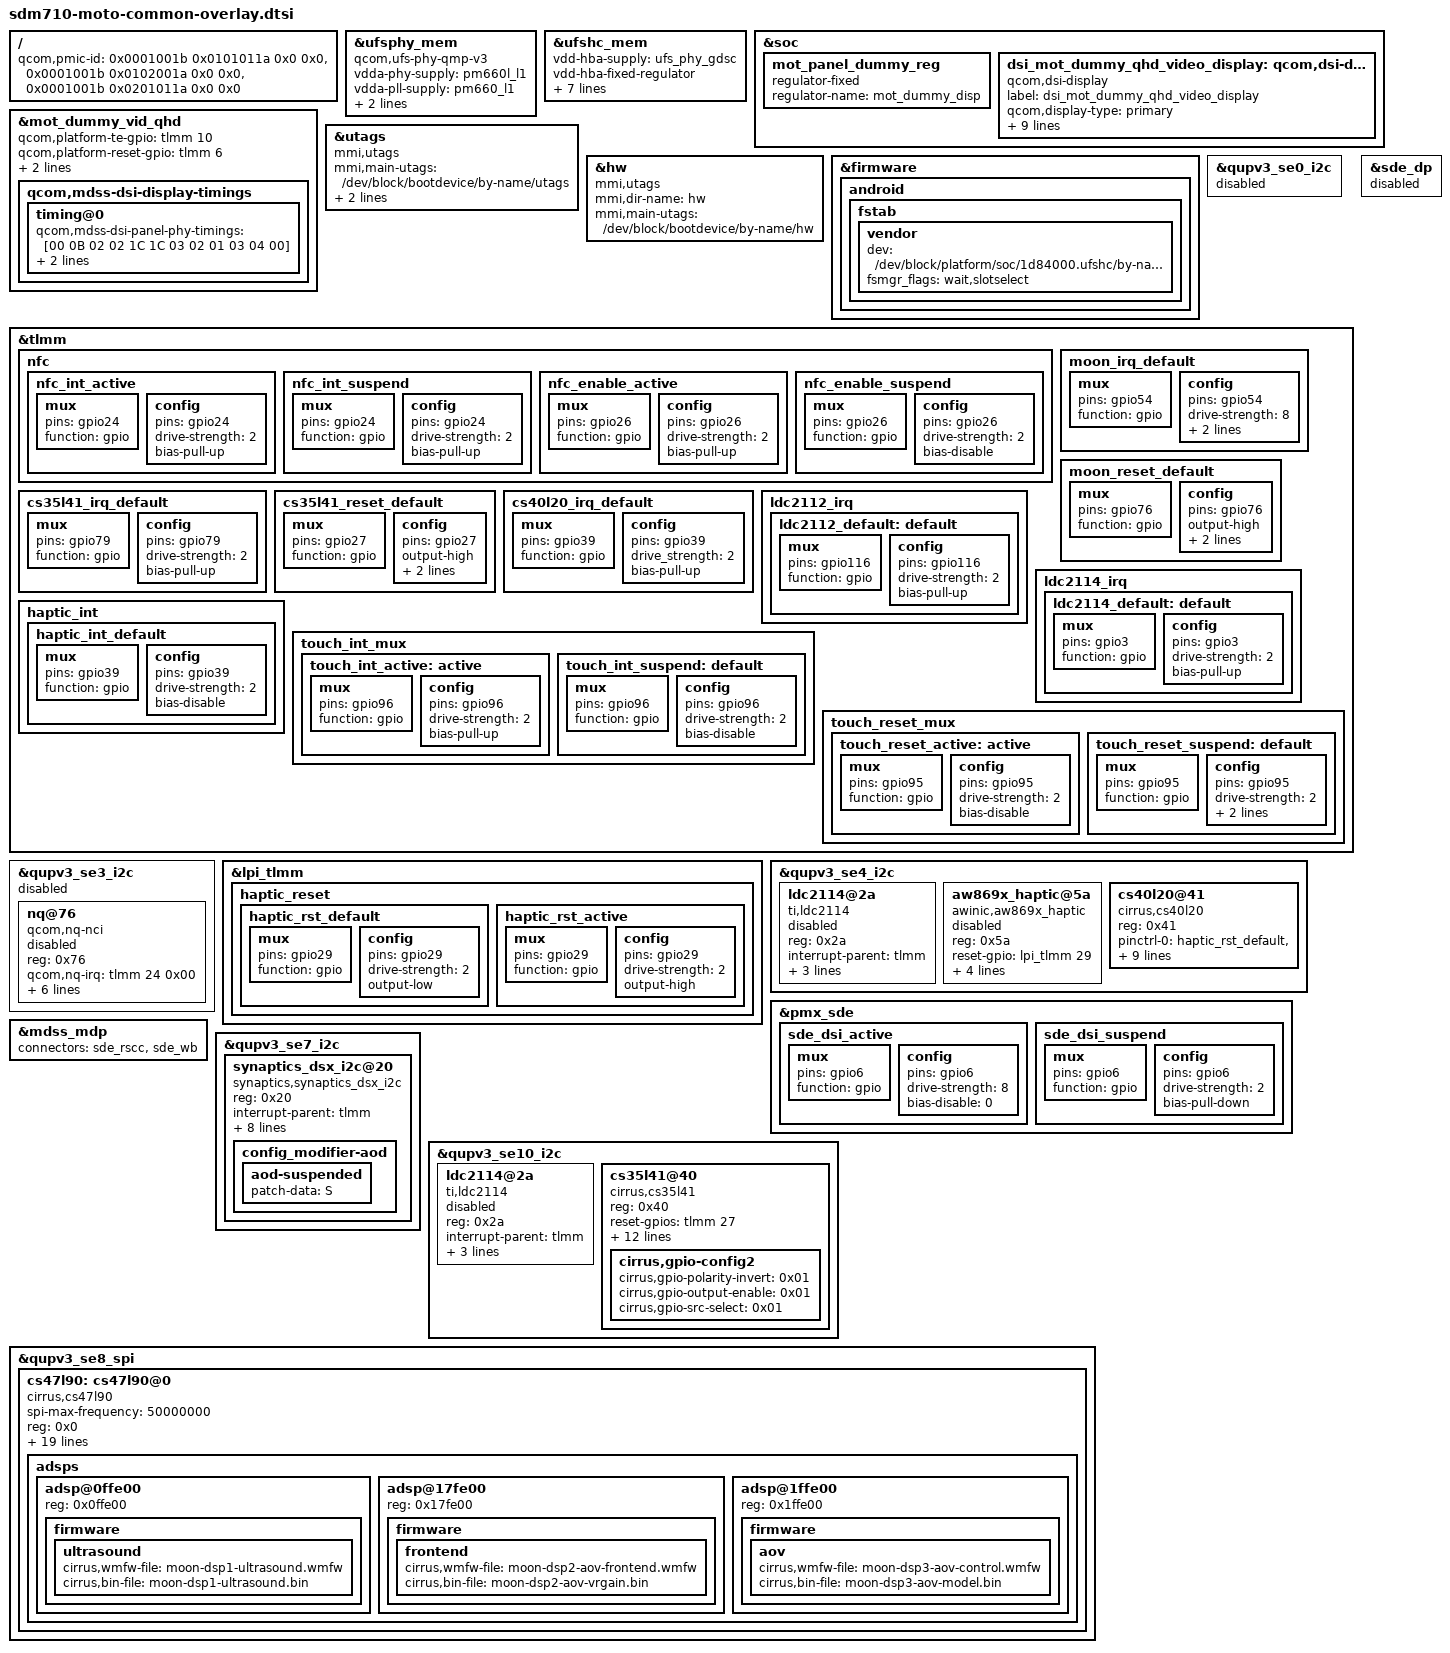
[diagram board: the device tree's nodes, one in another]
/* Copyright (c) 2018, The Linux Foundation. All rights reserved.
 *
 * This program is free software; you can redistribute it and/or modify
 * it under the terms of the GNU General Public License version 2 and
 * only version 2 as published by the Free Software Foundation.
 *
 * This program is distributed in the hope that it will be useful,
 * but WITHOUT ANY WARRANTY; without even the implied warranty of
 * MERCHANTABILITY or FITNESS FOR A PARTICULAR PURPOSE.  See the
 * GNU General Public License for more details.
 */

#include <dt-bindings/gpio/gpio.h>
#include <dt-bindings/input/input.h>
#include <dt-bindings/thermal/thermal.h>
#include <dt-bindings/clock/qcom,gcc-sdm845.h>
#include <dt-bindings/clock/qcom,camcc-sdm845.h>
#include <dt-bindings/clock/qcom,dispcc-sdm845.h>
#include <dt-bindings/clock/qcom,rpmh.h>
#include <dt-bindings/interrupt-controller/arm-gic.h>
#include "sdm670-pmic-overlay.dtsi"
#include "dsi-panel-mot-dummy-qhd-video.dtsi"
#include "sdm710-moto-audio-overlay.dtsi"

/*
 * Including features only applicable to Olson here
 */
/ {
	qcom,pmic-id = <0x0001001b 0x0101011a 0x0 0x0>,
		       <0x0001001b 0x0102001a 0x0 0x0>,
		       <0x0001001b 0x0201011a 0x0 0x0>;
};

&ufsphy_mem {
	compatible = "qcom,ufs-phy-qmp-v3";

	vdda-phy-supply = <&pm660l_l1>; /* 0.88v */
	vdda-pll-supply = <&pm660_l1>; /* 1.2v */
	vdda-phy-max-microamp = <62900>;
	vdda-pll-max-microamp = <18300>;

	status = "ok";
};

&ufshc_mem {
	vdd-hba-supply = <&ufs_phy_gdsc>;
	vdd-hba-fixed-regulator;
	vcc-supply = <&pm660l_l4>;
	vcc-voltage-level = <2960000 2960000>;
	vccq2-supply = <&pm660_l8>;
	vcc-max-microamp = <600000>;
	vccq2-max-microamp = <600000>;

	qcom,vddp-ref-clk-supply = <&pm660_l1>;
	qcom,vddp-ref-clk-max-microamp = <100>;

	status = "ok";
};

&soc {
	mot_panel_dummy_reg: mot_panel_dummy_reg {
		compatible = "regulator-fixed";
		regulator-name = "mot_dummy_disp";
	};


	dsi_mot_dummy_qhd_video_display: qcom,dsi-display@19 {
		compatible = "qcom,dsi-display";
		label = "dsi_mot_dummy_qhd_video_display";
		qcom,display-type = "primary";
		qcom,dsi-display-active;

		qcom,dsi-ctrl = <&mdss_dsi0>;
		qcom,dsi-phy = <&mdss_dsi_phy0>;
		clocks = <&mdss_dsi0_pll BYTECLK_MUX_0_CLK>,
			<&mdss_dsi0_pll PCLK_MUX_0_CLK>;
		clock-names = "src_byte_clk", "src_pixel_clk";

		pinctrl-names = "panel_active", "panel_suspend";
		pinctrl-0 = <&sde_dsi_active>;
		pinctrl-1 = <&sde_dsi_suspend>;

		qcom,dsi-panel = <&mot_dummy_vid_qhd>;
		vci_disp-supply = <&mot_panel_dummy_reg>;
	};
};

&mot_dummy_vid_qhd {
	qcom,platform-te-gpio = <&tlmm 10 0>;
	qcom,platform-reset-gpio = <&tlmm 6 0>;
	qcom,mdss-dsi-t-clk-post = <0x09>;
	qcom,mdss-dsi-t-clk-pre = <0x15>;
	qcom,mdss-dsi-display-timings {
		timing@0{
			qcom,mdss-dsi-panel-phy-timings = [00 0B 02 02 1C 1C 03
							02 01 03 04 00];
			qcom,display-topology = <1 0 1>;
			qcom,default-topology-index = <0>;
		};
	};
};

&utags {
	compatible = "mmi,utags";
	mmi,main-utags = "/dev/block/bootdevice/by-name/utags";
	mmi,backup-utags = "/dev/block/bootdevice/by-name/utagsBackup";
};

&hw {
	compatible = "mmi,utags";
	mmi,dir-name = "hw";
	mmi,main-utags = "/dev/block/bootdevice/by-name/hw";
};

&firmware {
	android {
		fstab {
			vendor {
				dev = "/dev/block/platform/soc/1d84000.ufshc/by-name/vendor";
				fsmgr_flags = "wait,slotselect";
			};
		};
	};
};

&qupv3_se0_i2c { /* FIXME: Main Proximity, Magnetometer, Barometer, Cirrus Codec */
	status = "disabled";
};

&tlmm {
	nfc {
		nfc_int_active: nfc_int_active {
			mux {
				pins = "gpio24";
				function = "gpio";
			};

			config {
				pins = "gpio24";
				drive-strength = <2>; /* 2 MA */
				bias-pull-up;
			};
		};

		nfc_int_suspend: nfc_int_suspend {
			mux {
				pins = "gpio24";
				function = "gpio";
			};

			config {
				pins = "gpio24";
				drive-strength = <2>; /* 2 MA */
				bias-pull-up;
			};
		};

		nfc_enable_active: nfc_enable_active {
			mux {
				pins = "gpio26";
				function = "gpio";
			};

			config {
				pins = "gpio26";
				drive-strength = <2>; /* 2 MA */
				bias-pull-up;
			};
		};

		nfc_enable_suspend: nfc_enable_suspend {
			mux {
				pins = "gpio26";
				function = "gpio";
			};

			config {
				pins = "gpio26";
				drive-strength = <2>; /* 2 MA */
				bias-disable;
			};
		};
	};

	moon_irq_default: moon_irq_default {
		mux {
			pins = "gpio54";
			function = "gpio";
		};

		config {
			pins = "gpio54";
			drive-strength = <8>;
			bias-pull-up;
			/* FIXME - to avoid interrupt storm */
			output-high;
		};
	};

	moon_reset_default: moon_reset_default {
		mux {
			pins = "gpio76";
			function = "gpio";
		};
		config {
			pins = "gpio76";
			output-high;
			bias-pull-up;
			drive-strength = <2>;
		};
	};

	cs35l41_irq_default: cs35l41_irq_default {
		mux {
			pins = "gpio79";
			function = "gpio";
		};
		config {
			pins = "gpio79";
			drive-strength = <2>;
			bias-pull-up;
		};
	};

	cs35l41_reset_default: cs35l41_reset_default {
		mux {
			pins = "gpio27";
			function = "gpio";
		};
		config {
			pins = "gpio27";
			output-high;
			bias-pull-up;
			drive-strength = <2>;
		};
	};

	cs40l20_irq_default: cs40l20_irq_default {
		mux {
			pins = "gpio39";
			function = "gpio";
		};
		config {
			pins = "gpio39";
			drive_strength = <2>;
			bias-pull-up;
		};
	};
};

&qupv3_se3_i2c {
	status = "disabled";
	nq@76 { /* FIXME: enable bus as well when ready */
		status = "disabled";
		compatible = "qcom,nq-nci";
		reg = <0x76>;
		qcom,nq-irq = <&tlmm 24 0x00>;
		qcom,nq-ven = <&tlmm 26 0x00>;
		qcom,nq-firm = <&tlmm 43 0x00>;
		interrupt-parent = <&tlmm>;
		interrupts = <24 0>;
		interrupt-names = "nfc_irq";
		pinctrl-names = "nfc_active", "nfc_suspend";
		pinctrl-0 = <&nfc_int_active &nfc_enable_active>;
		pinctrl-1 = <&nfc_int_suspend &nfc_enable_suspend>;
	};
};

&tlmm {
	ldc2112_irq { /* TI,LDC2112 */
		ldc2112_default: default {
			mux {
				pins = "gpio116";
				function = "gpio";
			};
			config {
				pins = "gpio116";
				drive-strength = <2>;
				bias-pull-up;
			};
		};
	};

	ldc2114_irq { /* TI,LDC2114 */
		ldc2114_default: default {
			mux {
				pins = "gpio3";
				function = "gpio";
			};
			config {
				pins = "gpio3";
				drive-strength = <2>;
				bias-pull-up;
			};
		};
	};

	haptic_int {
		haptic_int_default: haptic_int_default {
			mux {
				pins = "gpio39";
				function = "gpio";
			};

			config {
				pins = "gpio39";
				drive-strength = <2>; /* 2 mA */
				bias-disable;
			};
		};
	};
};


&lpi_tlmm {
	haptic_reset {
		haptic_rst_default: haptic_rst_default {
			mux {
				pins = "gpio29";
				function = "gpio";
			};

			config {
				pins = "gpio29";
				drive-strength = <2>; /* 2 mA */
				output-low;
			};
		};

		haptic_rst_active: haptic_rst_active {
			mux {
				pins = "gpio29";
				function = "gpio";
			};

			config {
				pins = "gpio29";
				drive-strength = <2>; /* 2 mA */
				output-high;
			};
		};
	};
};

&qupv3_se4_i2c { /* FIXME: LP4 Fan, Main Board FuelGauge, Base InductiveKeys, HapticDriver */
	status = "okay";
	ldc2114@2a {
		status = "disabled";
		compatible = "ti,ldc2114";
		reg = <0x2a>;
		interrupt-parent = <&tlmm>;
		interrupts = <116 0>;
		gpios = <&tlmm 13 0>;
		pinctrl-names = "default";
		pinctrl-0 = <&ldc2112_default>;
	};

	aw869x_haptic@5a {
		status = "disabled";
		compatible = "awinic,aw869x_haptic";
		reg = <0x5a>;
		reset-gpio = <&lpi_tlmm 29 0>;
		irq-gpio = <&tlmm 39 0>;
		pinctrl-names = "aw869x_rst0", "aw869x_rst1", "aw869x_eint";
		pinctrl-0 = <&haptic_rst_default>;
		pinctrl-1 = <&haptic_rst_active>;
		pinctrl-2 = <&haptic_int_default>;
	};

	cs40l20@41 {
		status = "ok";
		compatible = "cirrus,cs40l20";
		reg = <0x41>;
		pinctrl-names = "default";
		pinctrl-0 = <&haptic_rst_default &cs40l20_irq_default>;
		reset-gpios = <&lpi_tlmm 29 0>;
		irq-gpios = <&tlmm 39 0>;
		interrupt-parent = <&tlmm>;
		VA-supply = <&pm660_l13>;
		clock-names = "hap_ref_clk";
		clocks = <&clock_audio_lnbb AUDIO_PMIC_LNBB_CLK>;
		cirrus,boost-ind-nanohenry = <1000>;
		cirrus,boost-cap-microfarad = <4>;
		cirrus,boost-ipk-milliamp = <4500>;
	};

};

&tlmm {
	touch_int_mux {
		touch_int_active: active {
			mux {
				pins = "gpio96";
				function = "gpio";
			};
			config {
				pins = "gpio96";
				drive-strength = <2>;
				bias-pull-up;
			};
		};

		touch_int_suspend: default {
			mux {
				pins = "gpio96";
				function = "gpio";
			};
			config {
				pins = "gpio96";
				drive-strength = <2>;
				bias-disable;
			};
		};
	};

	touch_reset_mux {
		touch_reset_active: active {
			mux {
				pins = "gpio95";
				function = "gpio";
			};
			config {
				pins = "gpio95";
				drive-strength = <2>;
				bias-disable;
			};
		};

		touch_reset_suspend: default {
			mux {
				pins = "gpio95";
				function = "gpio";
			};
			config {
				pins = "gpio95";
				drive-strength = <2>;
				bias-pull-down;
				output-low;
			};
		};
	};
};

&pmx_sde {
	sde_dsi_active: sde_dsi_active {
		mux {
			pins = "gpio6";
			function = "gpio";
		};

		config {
			pins = "gpio6";
			drive-strength = <8>;    /* 8 mA */
			bias-disable = <0>;   /* no pull */
		};
	};

	sde_dsi_suspend: sde_dsi_suspend {
		mux {
			pins = "gpio6";
			function = "gpio";
		};

		config {
			pins = "gpio6";
			drive-strength = <2>;    /* 2 mA */
			bias-pull-down;          /* PULL DOWN */
		};
	};
};

&sde_dp {
	status = "disabled";
};

&mdss_mdp {
	connectors = <&sde_rscc &sde_wb>;
};

&qupv3_se7_i2c {
	status = "ok";
	synaptics_dsx_i2c@20 {
		status = "ok";
		compatible = "synaptics,synaptics_dsx_i2c";
		reg = <0x20>;
		interrupt-parent = <&tlmm>;
		interrupts = <96 0>;
		gpios = <&tlmm 96 0>, /* IRQ */
			<&tlmm 95 0>; /* RESET */
		synaptics,gpio-config;
		pinctrl-names = "default", "active";
		pinctrl-0 = <&touch_reset_suspend &touch_int_suspend>;
		pinctrl-1 = <&touch_reset_active &touch_int_active>;
		config_modifier-names = "aod";
		config_modifier-aod {
			aod-suspended {
				/* Power->sleep; */
				patch-data = "S";
			};
		};
	};
};

&qupv3_se10_i2c { /* FIXME: CapSence, Womack, FLIP FuelGauge, InductiveKeys, Laser, LS Fan */
	status = "ok";

	ldc2114@2a {
		status = "disabled";
		compatible = "ti,ldc2114";
		reg = <0x2a>;
		interrupt-parent = <&tlmm>;
		interrupts = <3 0>;
		gpios = <&tlmm 16 0>;
		pinctrl-names = "default";
		pinctrl-0 = <&ldc2114_default>;
	};

	cs35l41@40 {
		status = "ok";
		compatible = "cirrus,cs35l41";
		reg = <0x40>;
		reset-gpios = <&tlmm 27 0>;
		interrupts = <79 0>;
		interrupt-parent = <&tlmm>;
		interrupt-names = "prince_irq";

		VA-supply = <&pm660_l13>;
		VP-supply = <&pm660_l13>;

		pinctrl-names = "default";
		pinctrl-0 = <&cs35l41_irq_default &cs35l41_reset_default>;

		cirrus,left-channel-amp;
		cirrus,boost-ind-nanohenry = <1000>; /* 1uH */
		cirrus,boost-ctl-millivolt = <11000>;
		cirrus,boost-peak-milliamp = <4500>;
		cirrus,boost-cap-microfarad = <21>;
		cirrus,amp-gain-zc;

		cirrus,gpio-config2 {
			cirrus,gpio-polarity-invert = <0x01>;
			cirrus,gpio-output-enable = <0x01>;
			cirrus,gpio-src-select = <0x01>;
		};
	};
};

&qupv3_se8_spi { /* Cirrus Audio */
	status = "ok";
	cs47l90: cs47l90@0 {
		compatible = "cirrus,cs47l90";
		spi-max-frequency = <50000000>;
		reg = <0x0>;
		interrupt-parent = <&tlmm>;
		interrupts = <54 0>;
		interrupt-controller;
		#interrupt-cells = <2>;
		reset-gpios = <&tlmm 78 0>;
		pinctrl-names = "default";
		pinctrl-0 = <&moon_irq_default &moon_reset_default>;

		AVDD-supply = <&pm660_l13>;
		DBVDD1-supply = <&pm660_l13>;
		DBVDD2-supply = <&pm660_l13>;
		CPVDD-supply = <&pm660_l13>;
		CPVDD1-supply = <&pm660_l13>;
		CPVDD2-supply = <&pm660_l13>;
		DCVDD-supply = <&pm660_l13>;

		gpio-controller;
		#gpio-cells = <2>;
		cirrus,gpio-defaults = <
		0x00002000 0x0000f000 /* CDC_DEBUG / GPIO1 */
		0x00002000 0x0000f000 /* ADSP_WAKE / GPIO2 */
		0x00000040 0x00000000 /* SB_MCLK / GPIO3 */
		0xffffffff 0xffffffff /* USBC-HS / GPIO4 */
		0xffffffff 0xffffffff /* USBC-HS / GPIO5 */
		0xffffffff 0xffffffff /* GPIO6 */
		0xffffffff 0xffffffff /* GPIO7 */
		0xffffffff 0xffffffff /* GPIO8 */
		0xffffffff 0xffffffff /* GPIO9 */
		0xffffffff 0xffffffff /* GPIO10 */
		0xffffffff 0xffffffff /* GPIO11 */
		0xffffffff 0xffffffff /* GPIO12 */
		0xffffffff 0xffffffff /* GPIO13 */
		0xffffffff 0xffffffff /* GPIO14 */
		0x00002000 0x0000f000 /* AIF1TXDAT / GPIO15 */
		0x00002000 0x0000f000 /* AIF1BCLK / GPIO16 */
		0x00002000 0x0000f000 /* AIF1RXDAT / GPIO17 */
		0x00002000 0x0000f000 /* AIF1LRCLK / GPIO18 */
		0x00002000 0x0000f000 /* AIF2TXDAT / GPIO19 */
		0x00002000 0x0000f000 /* AIF2BCLK / GPIO20 */
		0x00002000 0x0000f000 /* AIF2RXDAT / GPIO21 */
		0x00002000 0x0000f000 /* AIF2LRCLK / GPIO22 */
		0xffffffff 0xffffffff /* GPIO23 */
		0xffffffff 0xffffffff /* GPIO24 */
		0xffffffff 0xffffffff /* GPIO25 */
		0xffffffff 0xffffffff /* GPIO26 */
		0xffffffff 0xffffffff /* GPIO27 */
		0xffffffff 0xffffffff /* GPIO28 */
		0xffffffff 0xffffffff /* GPIO29 */
		0xffffffff 0xffffffff /* GPIO30 */
		0xffffffff 0xffffffff /* GPIO31 */
		0xffffffff 0xffffffff /* GPIO32 */
		0xffffffff 0xffffffff /* GPIO33 */
		0xffffffff 0xffffffff /* GPIO34 */
		0xffffffff 0xffffffff /* GPIO35 */
		0xffffffff 0xffffffff /* GPIO36 */
		0xffffffff 0xffffffff /* GPIO37 */
		0xffffffff 0xffffffff /* GPIO38 */
		>;


		cirrus,micbias1 = <2600 1 1 1 1 1 1 0>;
		cirrus,micbias2 = <2600 1 1 1 1 1 1 0>;
		cirrus,inmode = <
				0 0 0 0
				0 0 0 0
				>;
		adsps {
			#address-cells = <1>;
			#size-cells = <0>;
			adsp@0ffe00 {
				reg = <0x0ffe00>;
				firmware {
					ultrasound {
						cirrus,wmfw-file = "moon-dsp1-ultrasound.wmfw";
						cirrus,bin-file = "moon-dsp1-ultrasound.bin";
					};
				};
			};
			adsp@17fe00 {
				reg = <0x17fe00>;
				firmware {
					frontend {
						cirrus,wmfw-file = "moon-dsp2-aov-frontend.wmfw";
						cirrus,bin-file = "moon-dsp2-aov-vrgain.bin";
					};
				};
			};
			adsp@1ffe00 {
				reg = <0x1ffe00>;
				firmware {
					aov {
						cirrus,wmfw-file = "moon-dsp3-aov-control.wmfw";
						cirrus,bin-file = "moon-dsp3-aov-model.bin";
					};
				};
			};
		};
	};
};


